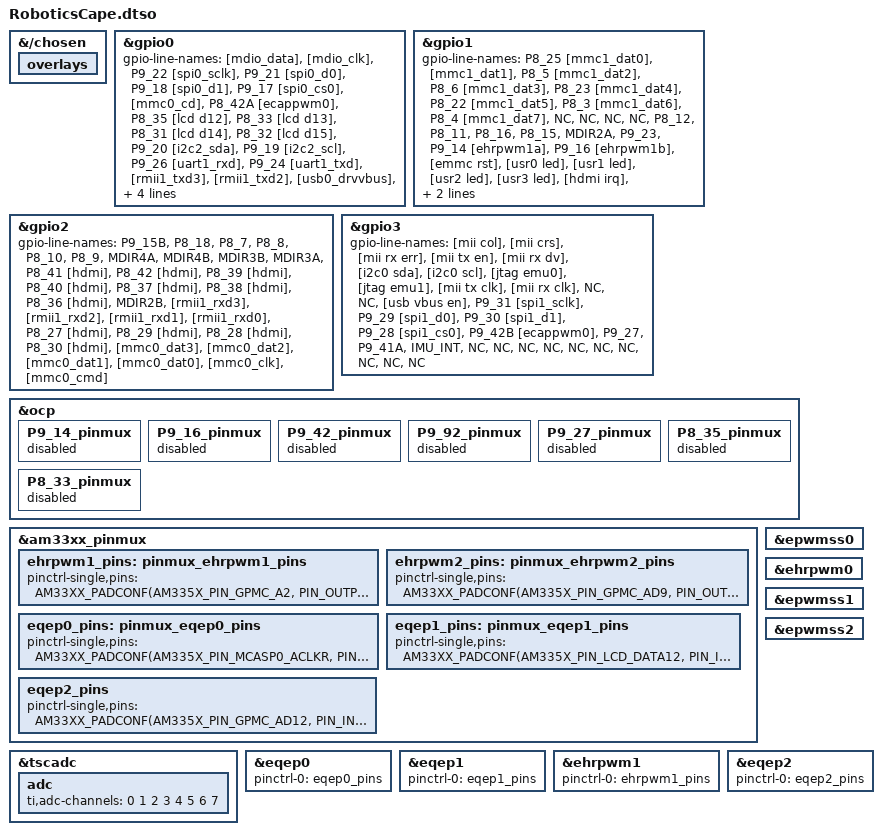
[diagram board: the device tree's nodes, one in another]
/dts-v1/;
/plugin/;

/* #include <dt-bindings/pinctrl/am33xx.h> */
/* #include <dt-bindings/gpio/gpio.h> */
/* #include <dt-bindings/interrupt-controller/irq.h> */

&{/chosen} {
    overlays {};
};

/*
 * Helper to show loaded overlays under: /proc/device-tree/chosen/overlays/
 */

/* 
	Reference: am335x-boneblue.dts
	
	ecapx + ehrpwmx are part of the epwmss system
	They need to be enabled individually!
	
	https://git.kernel.org/pub/scm/linux/kernel/git/stable/linux.git/tree/arch/arm/boot/dts/am335x-boneblue.dts?h=linux-6.1.y
	https://git.kernel.org/pub/scm/linux/kernel/git/stable/linux.git/tree/arch/arm/boot/dts/am33xx-l4.dtsi?h=linux-6.1.y
	
	Hints taken from this post: 
	https://github.com/beagleboard/BeagleBoard-DeviceTrees/pull/67
	https://github.com/beagleboard/BeagleBoard-DeviceTrees/pull/67/commits/0488dcbb863317c6be21b0682bbbd0216c5a5af7
*/

/*
 gpio0..3 taken from:
 /linux-ti-staging-rt/6.6.58+git/git/arch/arm/boot/dts/ti/omap/am335x-boneblack.dts
*/
&gpio0 {
	gpio-line-names =
		"[mdio_data]",
		"[mdio_clk]",
		"P9_22 [spi0_sclk]",
		"P9_21 [spi0_d0]",
		"P9_18 [spi0_d1]",
		"P9_17 [spi0_cs0]",
		"[mmc0_cd]",
		"P8_42A [ecappwm0]",
		"P8_35 [lcd d12]",
		"P8_33 [lcd d13]",
		"P8_31 [lcd d14]",
		"P8_32 [lcd d15]",
		"P9_20 [i2c2_sda]",
		"P9_19 [i2c2_scl]",
		"P9_26 [uart1_rxd]",
		"P9_24 [uart1_txd]",
		"[rmii1_txd3]",
		"[rmii1_txd2]",
		"[usb0_drvvbus]",
		"[hdmi cec]",
		"MOT_STBY",
		"[rmii1_txd1]",
		"P8_19 [ehrpwm2a]",
		"P8_13 [ehrpwm2b]",
		"NC",
		"NC",
		"P8_14",
		"P8_17",
		"[rmii1_txd0]",
		"[rmii1_refclk]",
		"P9_11 [uart4_rxd]",
		"MDIR1B";
};

&gpio1 {
	gpio-line-names =
		"P8_25 [mmc1_dat0]",
		"[mmc1_dat1]",
		"P8_5 [mmc1_dat2]",
		"P8_6 [mmc1_dat3]",
		"P8_23 [mmc1_dat4]",
		"P8_22 [mmc1_dat5]",
		"P8_3 [mmc1_dat6]",
		"P8_4 [mmc1_dat7]",
		"NC",
		"NC",
		"NC",
		"NC",
		"P8_12",
		"P8_11",
		"P8_16",
		"P8_15",
		"MDIR2A",
		"P9_23",
		"P9_14 [ehrpwm1a]",
		"P9_16 [ehrpwm1b]",
		"[emmc rst]",
		"[usr0 led]",
		"[usr1 led]",
		"[usr2 led]",
		"[usr3 led]",
		"[hdmi irq]",
		"[usb vbus oc]",
		"[hdmi audio]",
		"MDIR1A",
		"P8_26",
		"P8_21 [emmc]",
		"P8_20 [emmc]";
};

&gpio2 {
	gpio-line-names =
		"P9_15B",
		"P8_18",
		"P8_7",
		"P8_8",
		"P8_10",
		"P8_9",
		"MDIR4A",
		"MDIR4B",
		"MDIR3B",
		"MDIR3A",
		"P8_41 [hdmi]",
		"P8_42 [hdmi]",
		"P8_39 [hdmi]",
		"P8_40 [hdmi]",
		"P8_37 [hdmi]",
		"P8_38 [hdmi]",
		"P8_36 [hdmi]",
		"MDIR2B",
		"[rmii1_rxd3]",
		"[rmii1_rxd2]",
		"[rmii1_rxd1]",
		"[rmii1_rxd0]",
		"P8_27 [hdmi]",
		"P8_29 [hdmi]",
		"P8_28 [hdmi]",
		"P8_30 [hdmi]",
		"[mmc0_dat3]",
		"[mmc0_dat2]",
		"[mmc0_dat1]",
		"[mmc0_dat0]",
		"[mmc0_clk]",
		"[mmc0_cmd]";
};

&gpio3 {
	gpio-line-names =
		"[mii col]",
		"[mii crs]",
		"[mii rx err]",
		"[mii tx en]",
		"[mii rx dv]",
		"[i2c0 sda]",
		"[i2c0 scl]",
		"[jtag emu0]",
		"[jtag emu1]",
		"[mii tx clk]",
		"[mii rx clk]",
		"NC",
		"NC",
		"[usb vbus en]",
		"P9_31 [spi1_sclk]",
		"P9_29 [spi1_d0]",
		"P9_30 [spi1_d1]",
		"P9_28 [spi1_cs0]",
		"P9_42B [ecappwm0]",
		"P9_27",
		"P9_41A",
		"IMU_INT",
		"NC",
		"NC",
		"NC",
		"NC",
		"NC",
		"NC",
		"NC",
		"NC",
		"NC",
		"NC";
};

/* TODO: check if this freeing is still needed!
 *
 * Free up the pins used by the cape from the pinmux helpers.
 */
&ocp {

	/* TODO: Motor Control Pin frei geben */

	/* PWM1 */
	P9_14_pinmux { status = "disabled"; };	/* pwm: ehrpwm1a */
	P9_16_pinmux { status = "disabled"; };  /* pwm: ehrpwm1b */

	/* E1 */
	P9_42_pinmux { status = "disabled"; };	/* P9_42: gpmc_a1.gpio0_07 */
	P9_92_pinmux { status = "disabled"; };	/* P9_42.1: mcasp0_aclkr.gpio3_18 */
	P9_27_pinmux { status = "disabled"; };	/* P9_27: mcasp0_fsr.gpio3_19 */

	/* E2 */
	P8_35_pinmux { status = "disabled"; };	/* P8_35: (V2) lcd_data12.eQEP1A_in */
	P8_33_pinmux { status = "disabled"; };	/* P8_33: (V3) lcd_data13.eQEP1B_in */
};

/* partly taken from: am335x-boneblue.dts */
&am33xx_pinmux {
	ehrpwm1_pins: pinmux_ehrpwm1_pins {
		pinctrl-single,pins = <
			AM33XX_PADCONF(AM335X_PIN_GPMC_A2, PIN_OUTPUT, MUX_MODE6) /* P9_14 (U14) gpmc_a2.ehrpwm1A */
			AM33XX_PADCONF(AM335X_PIN_GPMC_A3, PIN_OUTPUT, MUX_MODE6) /* P9_16 (T14) gpmc_a3.ehrpwm1B */
		>;
	};

	ehrpwm2_pins: pinmux_ehrpwm2_pins {
		pinctrl-single,pins = <
			AM33XX_PADCONF(AM335X_PIN_GPMC_AD9, PIN_OUTPUT, MUX_MODE4) /* P8_13 (T10) gpmc_ad9.ehrpwm2B */
			AM33XX_PADCONF(AM335X_PIN_GPMC_AD8, PIN_OUTPUT, MUX_MODE4) /* P8_19 (U10) gpmc_ad8.ehrpwm2A */
		>;
	};

	/* E1
	 * Note: No external pull-down, therefore enable internal pull-down.
	 */
	eqep0_pins: pinmux_eqep0_pins {
		pinctrl-single,pins = <
			AM33XX_PADCONF(AM335X_PIN_MCASP0_ACLKR, PIN_INPUT_PULLDOWN, MUX_MODE1)	/* (B12) mcasp0_aclkr.eQEP0A_in */
			AM33XX_PADCONF(AM335X_PIN_MCASP0_FSR, PIN_INPUT_PULLDOWN, MUX_MODE1)	/* (C13) mcasp0_fsr.eQEP0B_in */
		>;
	};

	/* E2
	 * Note: according to schematics, both pins have external 100k pull-down resistors,
	 *       therefore disable the internal pull.
	 */
	eqep1_pins: pinmux_eqep1_pins {
		pinctrl-single,pins = <
			AM33XX_PADCONF(AM335X_PIN_LCD_DATA12, PIN_INPUT, MUX_MODE2)		/* (V2) lcd_data12.eQEP1A_in */
			AM33XX_PADCONF(AM335X_PIN_LCD_DATA13, PIN_INPUT, MUX_MODE2)		/* (V3) lcd_data13.eQEP1B_in */
		>;
	};

	/* E3 */
	eqep2_pins: eqep2_pins {
		pinctrl-single,pins = <
			AM33XX_PADCONF(AM335X_PIN_GPMC_AD12, PIN_INPUT, MUX_MODE4)		/* (T12) gpmc_ad12.eQEP2A_in */
			AM33XX_PADCONF(AM335X_PIN_GPMC_AD13, PIN_INPUT, MUX_MODE4)		/* (R12) gpmc_ad13.eQEP2B_in */
		>;
	};


};

/* provide data for symlinks */
/*
&uart0 {
	symlink = "bone/uart/0";
};
&uart2 {
	symlink = "bone/uart/2";
};
&i2c0 {
	symlink = "bone/i2c/0";
};
&i2c2 {
	symlink = "bone/i2c/2";
};
*/
/*
	Symlinks for:
		-> eqep => /sys/bus/counter/devices 
		   => dedicated udev rule [83-counter-noroot.rules]
		-> ehrpwm => /sys/class/pwm/ 
		   => dedicated udev rule [81-pwm-noroot.rule] 
		      + bb-symlinks.service + bb-symlinks.sh
*/

&tscadc {
	status = "okay";
	adc {
		ti,adc-channels = <0 1 2 3 4 5 6 7>;
	};
};

/*
&ecap0 {
	status="okay";
};
*/

&epwmss0 {
	status = "okay";
};

&eqep0 {
	pinctrl-names = "default";
	pinctrl-0 = <&eqep0_pins>;
	status = "okay";
};

&ehrpwm0 {
	status = "okay";
};

/*
&ecap1 {
	status="okay";
};
*/
&epwmss1 {
	status = "okay";
};

&eqep1 {
	pinctrl-names = "default";
	pinctrl-0 = <&eqep1_pins>;
	status = "okay";
};

&ehrpwm1 {
	pinctrl-names = "default";
	pinctrl-0 = <&ehrpwm1_pins>;
	status = "okay";
};

&epwmss2 {
	status = "okay";
};

&eqep2 {
	pinctrl-names = "default";
	pinctrl-0 = <&eqep2_pins>;
	status = "okay";
};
